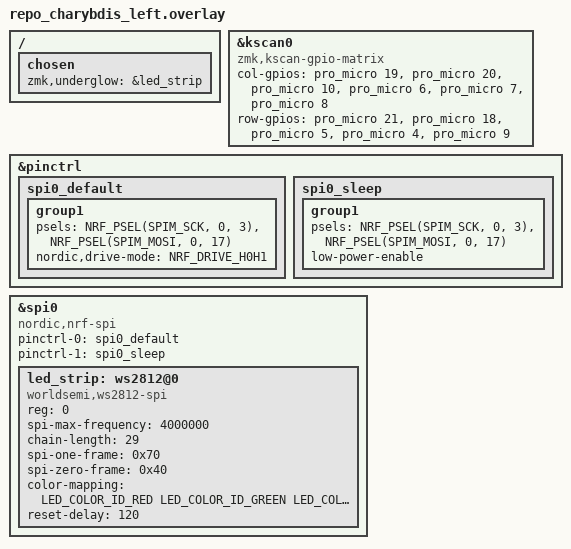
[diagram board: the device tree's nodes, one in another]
#include "charybdis.dtsi"
#include <dt-bindings/led/led.h>
#include <zephyr/dt-bindings/pinctrl/nrf-pinctrl.h>

&kscan0 {
	compatible = "zmk,kscan-gpio-matrix";

	col-gpios
		= <&pro_micro 19 (GPIO_ACTIVE_HIGH | GPIO_PULL_DOWN)>
		, <&pro_micro 20 (GPIO_ACTIVE_HIGH | GPIO_PULL_DOWN)>
		, <&pro_micro 10 (GPIO_ACTIVE_HIGH | GPIO_PULL_DOWN)>
		, <&pro_micro 6 (GPIO_ACTIVE_HIGH | GPIO_PULL_DOWN)>
		, <&pro_micro 7 (GPIO_ACTIVE_HIGH | GPIO_PULL_DOWN)>
		, <&pro_micro 8 (GPIO_ACTIVE_HIGH | GPIO_PULL_DOWN)>
		;

	row-gpios
   	        = <&pro_micro 21  GPIO_ACTIVE_HIGH>
                , <&pro_micro 18  GPIO_ACTIVE_HIGH>
                , <&pro_micro 5  GPIO_ACTIVE_HIGH>
                , <&pro_micro 4  GPIO_ACTIVE_HIGH>
                , <&pro_micro 9 GPIO_ACTIVE_HIGH>
                ;
};

// --- RGB Underglow (SK6812 MINI-E LEDs) ---
// DIN on P0.17, using spi0 in non-DMA mode with dummy SCK on P0.03
&pinctrl {
    spi0_default: spi0_default {
        group1 {
            psels = <NRF_PSEL(SPIM_SCK, 0, 3)>,
                    <NRF_PSEL(SPIM_MOSI, 0, 17)>;
            nordic,drive-mode = <NRF_DRIVE_H0H1>;
        };
    };

    spi0_sleep: spi0_sleep {
        group1 {
            psels = <NRF_PSEL(SPIM_SCK, 0, 3)>,
                    <NRF_PSEL(SPIM_MOSI, 0, 17)>;
            low-power-enable;
        };
    };
};

&spi0 {
    compatible = "nordic,nrf-spi";
    status = "okay";

    pinctrl-0 = <&spi0_default>;
    pinctrl-1 = <&spi0_sleep>;
    pinctrl-names = "default", "sleep";

    led_strip: ws2812@0 {
        compatible = "worldsemi,ws2812-spi";
        reg = <0>;
        spi-max-frequency = <4000000>;
        chain-length = <29>;
        spi-one-frame = <0x70>;
        spi-zero-frame = <0x40>;
        color-mapping = <LED_COLOR_ID_RED LED_COLOR_ID_GREEN LED_COLOR_ID_BLUE>;
        reset-delay = <120>;
    };
};

/ {
    chosen {
        zmk,underglow = &led_strip;
    };
};
